# PIC16LF1509 register map
Vendor: Microchip
Architecture 16Exxx. Special function registers and configuration words.
Registers are 8-bit, read-write, no defined reset value unless marked. A register's access mark holds for its fields unless they carry their own. Addresses are absolute, and some are shared; only a register's first bit layout is shown; lines under a group give offsets from that group; [hi:lo] are bit positions; {n}, {i} and the like mark numbered series; 'fields as' and 'values as' point back to an identical list; <NAME> marks a mode.

## Further device data
pins=1: VDD; 2: RA5/CLKIN/OSC1/T1CKI/NCO1CLK/SOSCI; 3: RA4/AN3/SOSCO/CLKOUT/OSC2/T1G; 4: RA3/CLC1IN0/VPP/T1G/SS/MCLR; 5: RC5/PWM1/CLC1/CWG1A; 6: RC4/C2OUT/CLC2IN1/CLC4/CWG1B; 7: RC3/AN7/C1IN3-/C2IN3-/PWM2/CLC2IN0; 8: RC6/AN8/NCO1/CLC3IN1/SS; 9: RC7/AN9/CLC1IN1/SDO; 10: RB7/CLC3/TX/CK; 11: RB6/SCL/SCK; 12: RB5/AN11/CLC4IN0/RX/DT; 13: RB4/AN10/CLC3IN0/SDA/SDI; 14: RC2/AN6/C1IN2-/C2IN2-; 15: RC1/AN5/C1IN1-/C2IN1-/PWM4/NCO1; 16: RC0/AN4/CLC2/C2IN+; 17: RA2/AN2/C1OUT/DACOUT2/T0CKI/INT/PWM3/CLC1/CWG1FLT; 18: RA1/AN1/CLC4IN1/VREF+/C1IN0-/C2IN0-/ICSPCLK/ICDCLK; 19: RA0/AN0/C1IN+/DACOUT1/ICSPDAT/ICDDAT; 20: VSS

## DOS_01444B
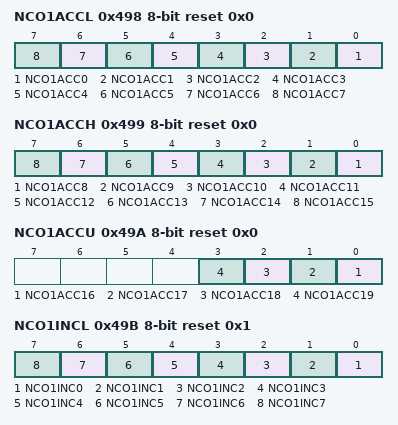
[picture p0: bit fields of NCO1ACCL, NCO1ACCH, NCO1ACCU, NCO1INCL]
0x498 NCO1ACCL reset 0x0
  [n] NCO1ACC{n} (n=0..7)
0x499 NCO1ACCH reset 0x0
  [n-8] NCO1ACC{n} (n=8..15)
0x49A NCO1ACCU reset 0x0
  [n-16] NCO1ACC{n} (n=16..19)
0x49B NCO1INCL reset 0x1
  [n] NCO1INC{n} (n=0..7)
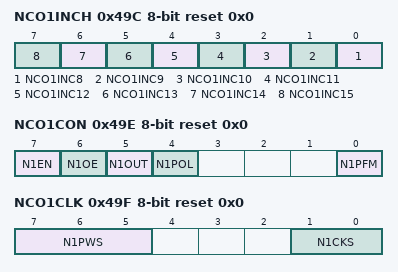
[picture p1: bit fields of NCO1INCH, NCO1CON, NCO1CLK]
0x49C NCO1INCH reset 0x0
  [n-8] NCO1INC{n} (n=8..15)
0x49D NCO1INCU access not given
0x49E NCO1CON reset 0x0 — Configurable logic cell control
  [7] N1EN, [6] N1OE, [5] N1OUT ro, [4] N1POL, [0] N1PFM
0x49F NCO1CLK reset 0x0
  [7:5] N1PWS, [1:0] N1CKS

## A4
0x691 CWG1DBR — (power-on value --xxxxxx)
  [5:0] CWG1DBR
0x692 CWG1DBF — (power-on value --xxxxxx)
  [5:0] CWG1DBF
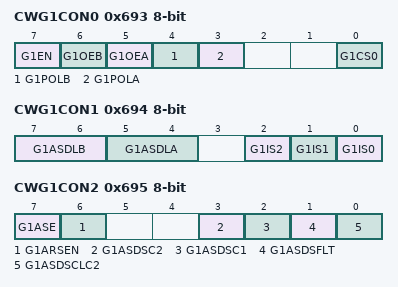
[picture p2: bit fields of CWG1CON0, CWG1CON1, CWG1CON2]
0x693 CWG1CON0 — Configurable logic cell control (power-on value 00000--x)
  [7] G1EN, [6] G1OEB, [5] G1OEA, [4] G1POLB, [3] G1POLA, [0] G1CS0
0x694 CWG1CON1 — (power-on value xxxx-xxx)
  [7:6] G1ASDLB, [5:4] G1ASDLA, [2] G1IS2, [1] G1IS1, [0] G1IS0
0x695 CWG1CON2 — (power-on value xx--xxxx)
  [7] G1ASE, [6] G1ARSEN, [3] G1ASDSC2, [2] G1ASDSC1, [1] G1ASDSFLT, [0] G1ASDSCLC2

## CLC_4xx
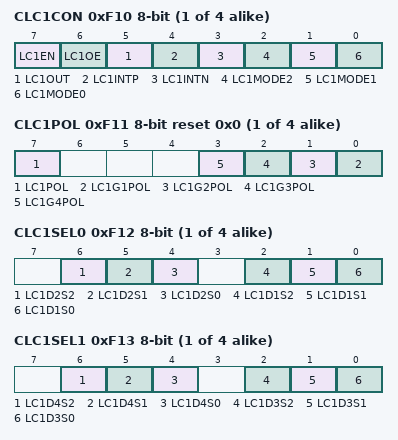
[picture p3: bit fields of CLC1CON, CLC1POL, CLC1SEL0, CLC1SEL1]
{0xF08+8i} CLC{i}CON (i=1..4) — Configurable logic cell control (power-on value 00u00000)
  [7] LC{i}EN, [6] LC{i}OE, [5] LC{i}OUT ro, [4] LC{i}INTP, [3] LC{i}INTN, [2] LC{i}MODE2, [1] LC{i}MODE1, [0] LC{i}MODE0
{0xF09+8i} CLC{i}POL reset 0x0 (i=1..4) — Polarity control
  [7] LC{i}POL, [n-1] LC{i}G{n}POL (n=1..4)
{0xF0A+8i} CLC{i}SEL0 (i=1..4) — Input select register 0 (power-on value -xxx-xxx)
  [6] LC{i}D2S2, [5] LC{i}D2S1, [4] LC{i}D2S0, [2] LC{i}D1S2, [1] LC{i}D1S1, [0] LC{i}D1S0
{0xF0B+8i} CLC{i}SEL1 (i=1..4) — Input select register 1 (power-on value -xxx-xxx)
  [6] LC{i}D4S2, [5] LC{i}D4S1, [4] LC{i}D4S0, [2] LC{i}D3S2, [1] LC{i}D3S1, [0] LC{i}D3S0
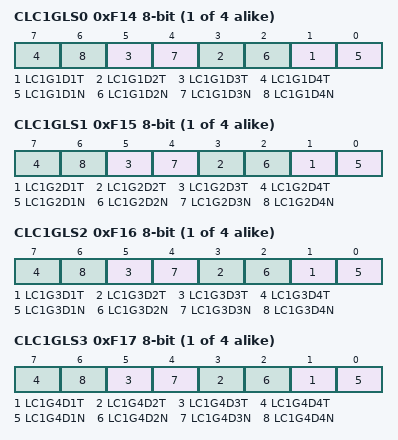
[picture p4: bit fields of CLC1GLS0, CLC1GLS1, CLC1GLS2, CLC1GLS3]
{0xF0C+8i} CLC{i}GLS0 (i=1..4) — Gate logic select register 0 (power-on value xxxxxxxx)
  [2n-1] LC{i}G1D{n}T (n=1..4), [2n-2] LC{i}G1D{n}N (n=1..4)
{0xF0D+8i} CLC{i}GLS1 (i=1..4) — Gate logic select register 1 (power-on value xxxxxxxx)
  [2n-1] LC{i}G2D{n}T (n=1..4), [2n-2] LC{i}G2D{n}N (n=1..4)
{0xF0E+8i} CLC{i}GLS2 (i=1..4) — Gate logic select register 2 (power-on value xxxxxxxx)
  [2n-1] LC{i}G3D{n}T (n=1..4), [2n-2] LC{i}G3D{n}N (n=1..4)
{0xF0F+8i} CLC{i}GLS3 (i=1..4) — Gate logic select register 3 (power-on value xxxxxxxx)
  [2n-1] LC{i}G4D{n}T (n=1..4), [2n-2] LC{i}G4D{n}N (n=1..4)

## CONFIG — Configuration words, addresses in ProgramSpace
0x8007 CONFIG1 14-bit reset 0x3FFF
  [13] FCMEN — Fail-Safe Clock Monitor Enable
    1=ON (Fail-Safe Clock Monitor is enabled); 0=OFF (Fail-Safe Clock Monitor is disabled)
  [12] IESO — Internal/External Switchover Mode
    1=ON (Internal/External Switchover Mode is enabled); 0=OFF (Internal/External Switchover Mode is disabled)
  [11] CLKOUTEN — Clock Out Enable
    1=OFF (CLKOUT function is disabled. I/O or oscillator function on the CLKOUT pin); 0=ON (CLKOUT function is enabled on the CLKOUT pin)
  [10:9] BOREN — Brown-out Reset Enable
    3=ON (Brown-out Reset enabled); 2=NSLEEP (Brown-out Reset enabled while running and disabled in Sleep); 1=SBODEN (Brown-out Reset controlled by the SBOREN bit in the BORCON register); 0=OFF (Brown-out Reset disabled)
  [7] CP — Flash Program Memory Code Protection
    1=OFF (Program memory code protection is disabled); 0=ON (Program memory code protection is enabled)
  [6] MCLRE — MCLR Pin Function Select
    1=ON (MCLR/VPP pin function is MCLR); 0=OFF (MCLR/VPP pin function is digital input)
  [5] PWRTE — Power-up Timer Enable
    1=OFF (PWRT disabled); 0=ON (PWRT enabled)
  [4:3] WDTE — Watchdog Timer Enable
    3=ON (WDT enabled); 2=NSLEEP (WDT enabled while running and disabled in Sleep); 1=SWDTEN (WDT controlled by the SWDTEN bit in the WDTCON register); 0=OFF (WDT disabled)
  [2:0] FOSC — Oscillator Selection Bits
    7=ECH (ECH, External Clock, High Power Mode (4-20 MHz): device clock supplied to CLKIN pins); 6=ECM (ECM, External Clock, Medium Power Mode (0.5-4 MHz): device clock supplied to CLKIN pins); 5=ECL (ECL, External Clock, Low Power Mode (0-0.5 MHz): device clock supplied to CLKIN pins); 4=INTOSC (INTOSC oscillator: I/O function on CLKIN pin); 3=EXTRC (EXTRC oscillator: External RC circuit connected to CLKIN pin); 2=HS (HS Oscillator, High-speed crystal/resonator connected between OSC1 and OSC2 pins); 1=XT (XT Oscillator, Crystal/resonator connected between OSC1 and OSC2 pins); 0=LP (LP Oscillator, Low-power crystal connected between OSC1 and OSC2 pins)
0x8008 CONFIG2 14-bit reset 0x3FFF
  [13] LVP — Low-Voltage Programming Enable
    1=ON (Low-voltage programming enabled); 0=OFF (High-voltage on MCLR/VPP must be used for programming)
  [11] LPBOR — Low-Power Brown Out Reset
    1=OFF (Low-Power BOR is disabled); 0=ON (Low-Power BOR is enabled)
  [10] BORV — Brown-out Reset Voltage Selection
    1=LO (Brown-out Reset Voltage (Vbor), low trip point selected.); 0=HI (Brown-out Reset Voltage (Vbor), high trip point selected.)
  [9] STVREN — Stack Overflow/Underflow Reset Enable
    1=ON (Stack Overflow or Underflow will cause a Reset); 0=OFF (Stack Overflow or Underflow will not cause a Reset)
  [1:0] WRT — Flash Memory Self-Write Protection
    3=OFF (Write protection off); 2=BOOT (000h to 1FFh write protected, 200h to 1FFFh may be modified by EECON control); 1=HALF (000h to FFFh write protected, 1000h to 1FFFh may be modified by EECON control); 0=ALL (000h to 1FFFh write protected, no addresses may be modified by EECON control)
